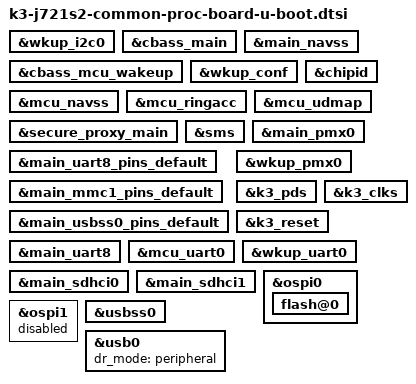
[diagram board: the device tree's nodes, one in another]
// SPDX-License-Identifier: GPL-2.0
/*
 * Copyright (C) 2021-2023 Texas Instruments Incorporated - https://www.ti.com/
 */

#include "k3-j721s2-binman.dtsi"

&wkup_i2c0 {
	bootph-all;
};

&cbass_main {
	bootph-all;
};

&main_navss {
	
};

&cbass_mcu_wakeup {
	bootph-all;
};

&wkup_conf {
	
};

&chipid {
	
};

&mcu_navss {
	
};

&mcu_ringacc {
	
};

&mcu_udmap {
	
};

&secure_proxy_main {
	
};

&sms {
	
};

&main_pmx0 {
	bootph-all;
};

&main_uart8_pins_default {
	
};

&main_mmc1_pins_default {
	
};

&main_usbss0_pins_default {
	
};

&wkup_pmx0 {
	
};

&k3_pds {
	
};

&k3_clks {
	
};

&k3_reset {
	
};

&main_uart8 {
	
};

&mcu_uart0 {
	
};

&wkup_uart0 {
	
};

&main_sdhci0 {
	
};

&main_sdhci1 {
	
};

&ospi0 {
	flash@0 {
		bootph-all;
	};
};

&ospi1 {
	status = "disabled";
};

&usbss0 {
	
};

&usb0 {
	dr_mode = "peripheral";
	bootph-all;
};
